VERSION "1"

NS_ :

BS_:

BU_: Ecu1 Ecu2

VAL_TABLE_ T 1 "a" 1 "b" ;
VAL_TABLE_ U 0 "z" ;
VAL_TABLE_ U 1 "w" ;

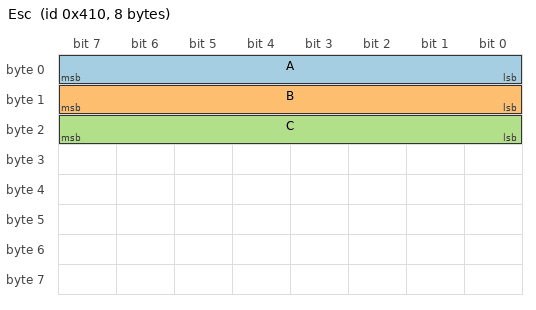
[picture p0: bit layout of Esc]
BO_ 1040 Esc: 8 Ecu1
 SG_ A : 0|8@1+ (1,0) [0|255] "" Ecu2
 SG_ B : 8|8@1+ (1,0) [0|255] "" Ecu2
 SG_ C : 16|8@1+ (1,0) [0|255] "" Ecu2

VAL_ 1040 A 0 "Say \"zero\"" 1 "back\\slash" 2 "semi;colon" ;
VAL_ 1040 B 1 "one" 1 "uno" 2 "two" ;
VAL_ 1040 C 0 "x" ;
VAL_ 1040 C 1 "y" ;
